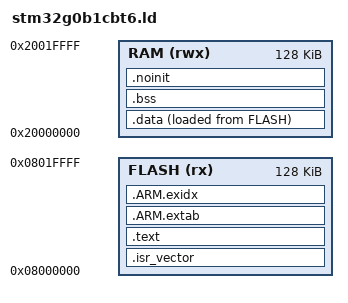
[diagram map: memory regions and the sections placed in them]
ENTRY(Reset_Handler)

MEMORY
{
    FLASH (rx)  : ORIGIN = 0x08000000, LENGTH = 128K
    RAM   (rwx) : ORIGIN = 0x20000000, LENGTH = 128K
}

_estack = ORIGIN(RAM) + LENGTH(RAM);

SECTIONS
{
    .isr_vector :
    {
        . = ALIGN(4);
        KEEP(*(.isr_vector))
        . = ALIGN(4);
    } > FLASH

    .text :
    {
        . = ALIGN(4);
        *(.text*)
        *(.rodata*)
        KEEP(*(.init))
        KEEP(*(.fini))
        . = ALIGN(4);
        _etext = .;
    } > FLASH

    .ARM.extab :
    {
        *(.ARM.extab* .gnu.linkonce.armextab.*)
    } > FLASH

    .ARM.exidx :
    {
        __exidx_start = .;
        *(.ARM.exidx* .gnu.linkonce.armexidx.*)
        __exidx_end = .;
    } > FLASH

    _sidata = LOADADDR(.data);

    .data :
    {
        . = ALIGN(4);
        _sdata = .;
        *(.data*)
        . = ALIGN(4);
        _edata = .;
    } > RAM AT > FLASH

    .bss (NOLOAD) :
    {
        . = ALIGN(4);
        _sbss = .;
        *(.bss*)
        *(COMMON)
        . = ALIGN(4);
        _ebss = .;
    } > RAM

    .noinit (NOLOAD) :
    {
        . = ALIGN(4);
        *(.noinit*)
        . = ALIGN(4);
    } > RAM

    /DISCARD/ :
    {
        *(.comment)
        *(.note*)
    }
}

ASSERT(SIZEOF(.isr_vector) >= 64, "Cortex-M0+ vector table is incomplete")
ASSERT(_ebss <= ORIGIN(RAM) + LENGTH(RAM), "STM32G0B1 RAM overflow")
